# Port_1_2_7 register map
Vendor: Texas Instruments
Peripheral module from a debugger description file (folder msp430).
Registers are 8-bit, read-write, reset 0x0 unless marked. A register's access mark holds for its fields unless they carry their own. Offsets are as the file gives them; lines under a group give offsets from that group; [hi:lo] are bit positions; {n}, {i} and the like mark numbered series; 'fields as' and 'values as' point back to an identical list; <NAME> marks a mode.

## Port_1/2
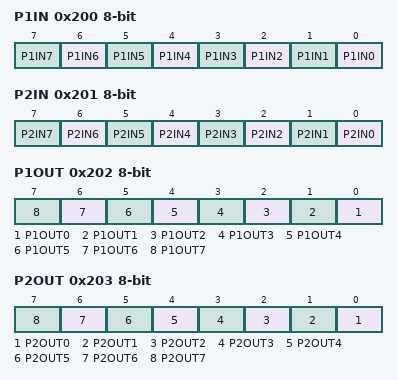
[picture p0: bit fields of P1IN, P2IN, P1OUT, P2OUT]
0x200 P1IN — Port 1 Input
  [n] P1IN{n} (n=0..7)
0x201 P2IN — Port 2 Input
  [n] P2IN{n} (n=0..7)
0x202 P1OUT — Port 1 Output
  [n] P1OUT{n} (n=0..7)
0x203 P2OUT — Port 2 Output
  [n] P2OUT{n} (n=0..7)
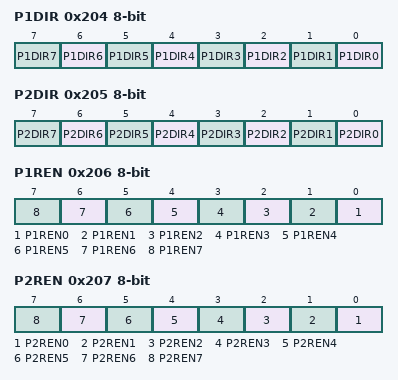
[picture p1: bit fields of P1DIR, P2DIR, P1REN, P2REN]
0x204 P1DIR — Port 1 Direction
  [n] P1DIR{n} (n=0..7)
0x205 P2DIR — Port 2 Direction
  [n] P2DIR{n} (n=0..7)
0x206 P1REN — Port 1 Resistor Enable
  [n] P1REN{n} (n=0..7)
0x207 P2REN — Port 2 Resistor Enable
  [n] P2REN{n} (n=0..7)
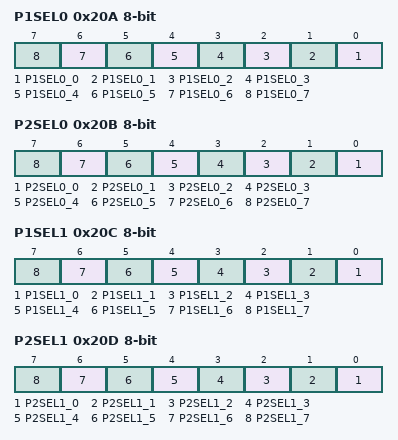
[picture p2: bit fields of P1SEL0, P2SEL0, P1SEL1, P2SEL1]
0x20A P1SEL0 — Port 1 Selection 0
  [n] P1SEL0_{n} (n=0..7)
0x20B P2SEL0 — Port 2 Selection 0
  [n] P2SEL0_{n} (n=0..7)
0x20C P1SEL1 — Port 1 Selection 1
  [n] P1SEL1_{n} (n=0..7)
0x20D P2SEL1 — Port 2 Selection 1
  [n] P2SEL1_{n} (n=0..7)
0x20E P1IV 16-bit access not given reset not defined — Port 1 Interrupt Vector Word
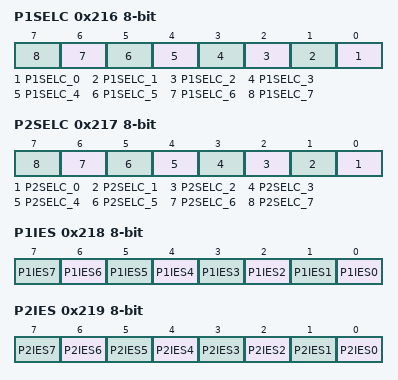
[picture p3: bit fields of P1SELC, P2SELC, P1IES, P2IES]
0x216 P1SELC — Port 1 Complement Selection
  [n] P1SELC_{n} (n=0..7)
0x217 P2SELC — Port 2 Complement Selection
  [n] P2SELC_{n} (n=0..7)
0x218 P1IES — Port 1 Interrupt Edge Select
  [n] P1IES{n} (n=0..7)
0x219 P2IES — Port 2 Interrupt Edge Select
  [n] P2IES{n} (n=0..7)
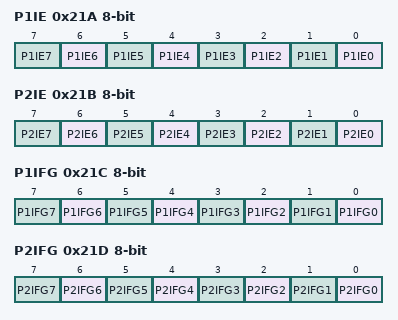
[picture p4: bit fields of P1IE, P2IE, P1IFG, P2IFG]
0x21A P1IE — Port 1 Interrupt Enable
  [n] P1IE{n} (n=0..7)
0x21B P2IE — Port 2 Interrupt Enable
  [n] P2IE{n} (n=0..7)
0x21C P1IFG — Port 1 Interrupt Flag
  [n] P1IFG{n} (n=0..7)
0x21D P2IFG — Port 2 Interrupt Flag
  [n] P2IFG{n} (n=0..7)
0x21E P2IV 16-bit access not given reset not defined — Port 2 Interrupt Vector Word
